# AT32UC3L0256 device description
Architecture: AVR32_UC3; Family: AVR UC3
Registers are 32-bit, read-write, reset 0x0 unless marked. A register's access mark holds for its fields unless they carry their own. Offsets are from the block's base; [hi:lo] are bit positions; {n}, {i} and the like mark numbered series; 'fields as' and 'values as' point back to an identical list.

## FLASHCDW — Flash Controller
Instances: FLASHCDW 0xfffe0000
Parameters: GPF_NUM=32
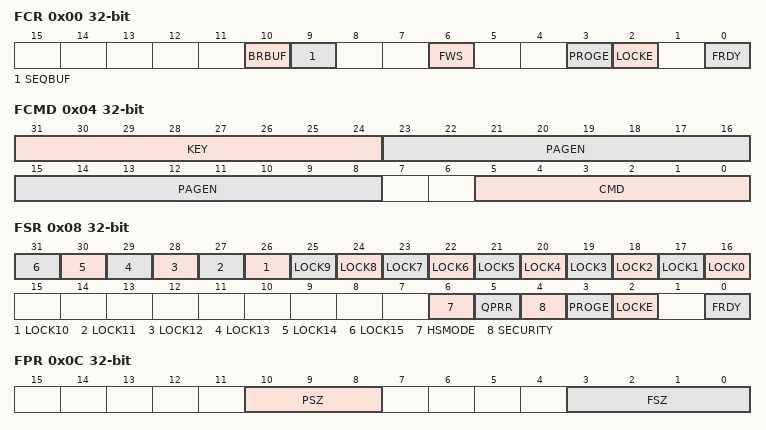
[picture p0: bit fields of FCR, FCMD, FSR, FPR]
0x00 FCR — Flash Controller Control Register
  [10] BRBUF — Branch Target Instruction Buffer Enable
  [9] SEQBUF — Sequential Instruction Fetch Buffer Enable
  [6] FWS — Flash Wait State
  [3] PROGE — Programming Error Interrupt Enable
  [2] LOCKE — Lock Error Interrupt Enable
  [0] FRDY — Flash Ready Interrupt Enable
0x04 FCMD — Flash Controller Command Register
  [31:24] KEY — Write protection key
    165=KEY
  [23:8] PAGEN — Page number
  [5:0] CMD — Command
    0=NOP; 1=WP; 2=EP; 3=CPB; 4=LP; 5=UP; 6=EA; 7=WGPB; 8=EGPB; 9=SSB; 10=PGPFB; 11=EAGPF; 12=QPR; 13=WUP; 14=EUP; 15=QPRUP; 16=HSEN; 17=HSDIS
0x08 FSR reset not defined — Flash Controller Status Register
  [n+16] LOCK{n} (n=0..15) — Lock Region {n} Lock Status
  [6] HSMODE — High Speed Mode
  [5] QPRR — Quick Page Read Result
  [4] SECURITY — Security Bit Status
  [3] PROGE — Programming Error Status
  [2] LOCKE — Lock Error Status
  [0] FRDY — Flash Ready Status
0x0C FPR ro reset not defined — Flash Controller Parameter Register
  [10:8] PSZ — Page Size
  [3:0] FSZ — Flash Size
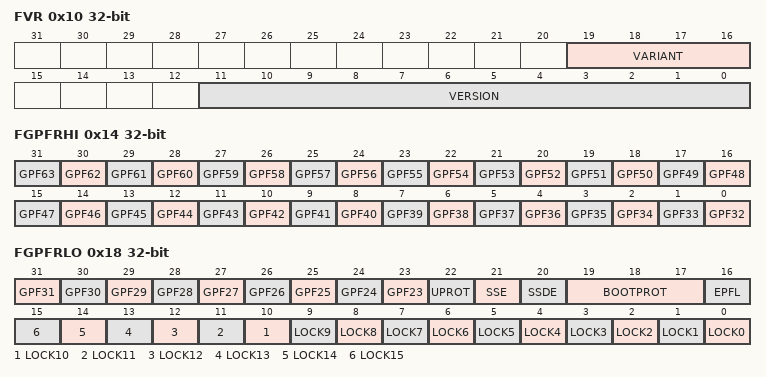
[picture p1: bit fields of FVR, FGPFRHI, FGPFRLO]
0x10 FVR ro reset not defined — Flash Controller Version Register
  [19:16] VARIANT — Variant Number
  [11:0] VERSION — Version Number
0x14 FGPFRHI ro reset not defined — Flash Controller General Purpose Fuse Register High
  [n-32] GPF{n} (n=32..63) — General Purpose Fuse {n}
0x18 FGPFRLO ro reset not defined — Flash Controller General Purpose Fuse Register Low
  [n] GPF{n} (n=23..31) — General Purpose Fuse {n}
  [22] UPROT — Jtag user protection
  [21] SSE — Secure state enable
  [20] SSDE — Secure state debug enable
  [19:17] BOOTPROT — Boot Section Protection size
  [16] EPFL — External Privileged mode fetch lock
  [n] LOCK{n} (n=0..15) — Lock Bit {n}

## FREQM — Frequency Meter
Instances: FREQM 0xffff2800
0x00 CTRL wo — Control register
  [0] START — Start frequency measurement
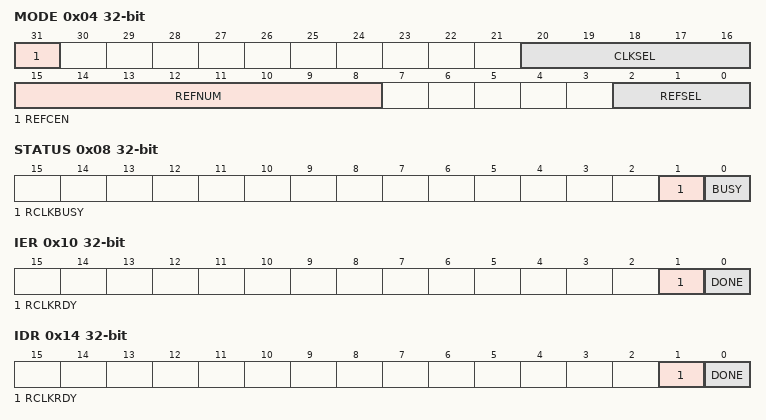
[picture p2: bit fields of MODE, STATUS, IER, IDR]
0x04 MODE
  [31] REFCEN — Reference Clock Enable
  [20:16] CLKSEL — Clock Source Selection
  [15:8] REFNUM — Number of Reference CLock Cycles
  [2:0] REFSEL — Reference Clock Selection
0x08 STATUS ro
  [1] RCLKBUSY — Reference Clock Busy
  [0] BUSY — Frequency measurement on-going
0x0C VALUE ro
  [23:0] VALUE — Measured frequency
0x10 IER wo — Interrupt Enable Register
  [1] RCLKRDY — Reference Clock ready
  [0] DONE — Frequency measurment done
0x14 IDR wo — Interrupt Diable Register
  fields as IER
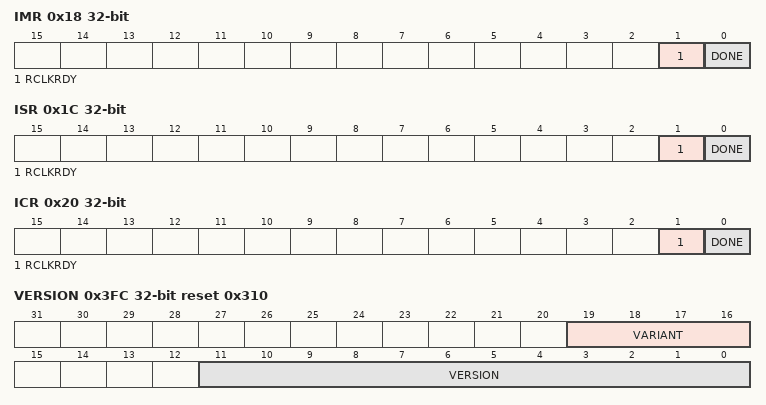
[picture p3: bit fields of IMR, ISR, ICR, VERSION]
0x18 IMR ro — Interrupt Mask Register
  fields as IER
0x1C ISR ro — Interrupt Status Register
  fields as IER
0x20 ICR wo — Interrupt Clear Register
  fields as IER
0x3FC VERSION ro reset 0x310
  [19:16] VARIANT — Variant number
  [11:0] VERSION — Version number

## USERPAGE_FUSES — Fuses
Instances: USERPAGE_FUSES 0x80800000
0x00 USERPAGE_WORD_0 reset 0xFFFFFFFF
  [0] WDTAUTO — Watch dog timer auto enable/disable at startup
    0=WDT_ENABLE (WDT is automatically enabled at startup); 1=WDT_DISABLE (WDT is not automatically enabled at startup)
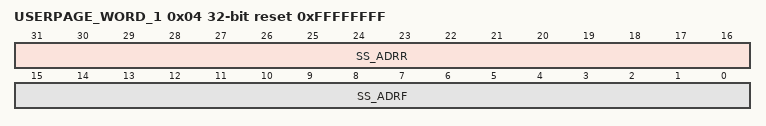
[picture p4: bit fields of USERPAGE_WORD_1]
0x04 USERPAGE_WORD_1 reset 0xFFFFFFFF
  [31:16] SS_ADRR — Size of the CPU RAM controlled by the Secure State
  [15:0] SS_ADRF — Size of the Flash controlled by the Secure State

## FLASH_FUSES — Fuses
Instances: FUSES 0xFFFE0000 in fuses
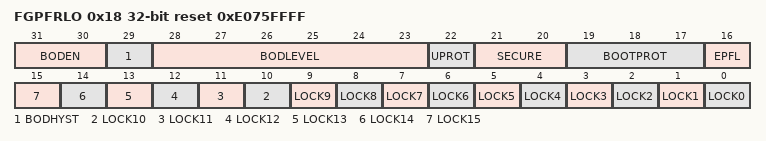
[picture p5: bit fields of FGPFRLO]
0x18 FGPFRLO reset 0xE075FFFF — Flash Controller General Purpose Fuse Register Low
  [31:30] BODEN — Brownout detector enable
    0=BOD_DISABLED; 1=BOD_ENABLED_RESET_ENABLED (BOD enabled, BOD reset enabled); 2=BOD_ENABLED_RESET_DISABLED (BOD enabled, BOD reset disabled); 3=BOD_DISABLED2
  [29] BODHYST — Brownout detector hysteresis
    0=BODHYST_DISABLED (Disabled); 1=BODHYST_ENABLED (Enabled)
  [28:23] BODLEVEL — Brownout detector trigger level
    0=BOD_LEVEL_OFF; 31=BOD_LEVEL_1V56 (BOD Level 1.56V); 39=BOD_LEVEL_1V65 (BOD Level 1.65V)
  [22] UPROT — JTAG user protection
    1=UPROT_ENABLE (Enable JTAG user protection); 0=UPROT_DISABLE (Disable JTAG user protection)
  [21:20] SECURE — Secure State
    0=SSDIS (Secure state disabled); 1=SSEN_SSDDIS (Secure enabled, secure state debug enabled); 2=SSEN_SSDEN (Secure enabled, secure state debug disabled); 3=SSDIS (Secure state disabled)
  [19:17] BOOTPROT — Bootloader protection
    0=BOOTAREA_64KB (Boot area: 64 Kbyte); 1=BOOTAREA_32KB (Boot area: 32 Kbyte); 2=BOOTAREA_16KB (Boot area: 16 Kbyte); 3=BOOTAREA_8KB (Boot area: 8 Kbyte); 4=BOOTAREA_4KB (Boot area: 4 Kbyte); 5=BOOTAREA_2KB (Boot area: 2 Kbyte); 6=BOOTAREA_1KB (Boot area: 1 Kbyte); 7=BOOTAREA_0B (Boot area: 0 byte)
  [16] EPFL — External privileged fetch lock
    0=EPFL_LOCK (External privileged fetch locked); 1=EPFL_NO_LOCK (External privileged fetch not locked)
  [n] LOCK{n} (n=0..15)
